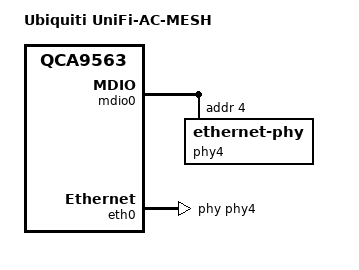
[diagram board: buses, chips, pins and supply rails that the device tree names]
// SPDX-License-Identifier: GPL-2.0-or-later OR MIT
/dts-v1/;

#include <dt-bindings/gpio/gpio.h>
#include <dt-bindings/input/input.h>

#include "qca9563_ubnt_unifiac.dtsi"

/ {
	compatible = "ubnt,unifiac-mesh", "qca,qca9563";
	model = "Ubiquiti UniFi-AC-MESH";
};

&mdio0 {
	status = "okay";

	phy-mask = <4>;
	phy4: ethernet-phy@4 {
		phy-mode = "sgmii";
		reg = <4>;
	};
};

&eth0 {
	status = "okay";

	mtd-mac-address = <&eeprom 0x0>;
	phy-handle = <&phy4>;
};
